# ADSP-2183xW_HPC register map
Vendor: Analog Devices; Series: ADSP-2183xW_HPC; File version: 3.0.3.517
CPU: 
Registers are 32-bit, read-write, reset 0x0 unless marked. A register's access mark holds for its fields unless they carry their own. Offsets are from the block's base; [hi:lo] are bit positions; {n}, {i} and the like mark numbered series.

## CTI1 — CSCTI_Register_Definitions
Base 0x31113000
0x00 CTICONTROL
  [0] GLBEN — Global CTI Enable
    0=DIS (Disable); 1=EN (Enable)
0x10 CTIINTACK — CTI Interrupt Acknowledge Register
  [7:0] INTACK range 0x00000000..0x000000FF — Interrupt Acknowledge
0x14 CTIAPPSET — CTI Application Trigger Set Register
  [3:0] APPSET range 0x00000000..0x0000000F — Set Channel Event
0x18 CTIAPPCLEAR — CTI Application Trigger Clear Register
  [3:0] APPCLEAR range 0x00000000..0x0000000F — Channel Clear
0x1C CTIAPPPULSE — CTI Application Pulse Register
  [3:0] Bit_0APPULSE range 0x00000000..0x0000000F — Channel Event Pulse
{0x20+4i} CTIINEN{i} (i=0..7) — CTI Trigger {i} to Channel Enable Register
  [3:0] TRIGINEN range 0x00000000..0x0000000F — Channel Trigger Input Enable
{0xA0+4i} CTIOUTEN{i} (i=0..7) — CTI Channel to Trigger {i} Enable Register
  [3:0] TRIGOUTEN range 0x00000000..0x0000000F — Channel Trigger Output Enable
0x130 CTITRIGINSTATUS — CTI Trigger In Status Register
  [7:0] TRIGINSTATUS ro — Trigger In Status
0x134 CTITRIGOUTSTATUS — CTI Trigger Out Status Register
  [7:0] TRIGOUTSTATUS ro — Trigger Output Status
0x138 CTICHINSTATUS — CTI Channel In Status Register
  [3:0] CTCHINSTATUS ro — Channel Input Status
0x13C CTICHOUTSTATUS — CTI Channel Out Status Register
  [3:0] CTCHOUTSTATUS ro — Channel Out Status
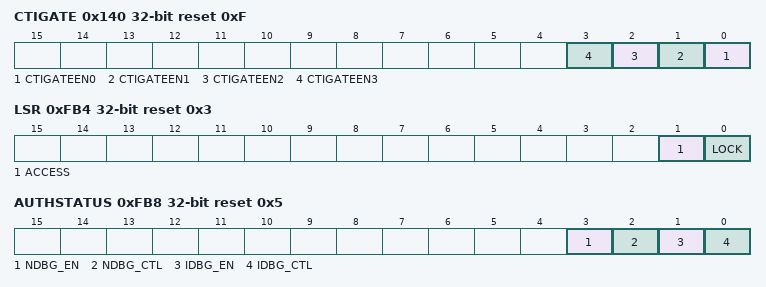
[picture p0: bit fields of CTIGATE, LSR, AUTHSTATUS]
0x140 CTIGATE reset 0xF — Enable CTI Channel Gate Register
  [n] CTIGATEEN{n} range 0x00000000..0x00000001 (n=0..3) — Enable CTICHOUT{n}
0x144 ASICCTL — External Multiplexor Control Register
  [7:0] ASICCTL range 0x00000000..0x000000FF — ASIC Control
0xEDC ITCHINACK
  [3:0] CTCHINACK range 0x00000000..0x0000000F — Set the value of the CTCHINACK outputs
0xEE0 ITTRIGINACK
  [7:0] CTTRIGINACK range 0x00000000..0x000000FF — Set the value of the CTTRIGINACK outputs
0xEE4 ITCHOUT — Integration Test Channel Output
  [3:0] CTCHOUT range 0x00000000..0x0000000F — Set CTCHOUT Output Value
0xEE8 ITTRIGOUT — Integration Test Trigger Output
  [7:0] CTTRIGOUT range 0x00000000..0x000000FF — Set the value of the CTTRIGOUT outputs
0xEEC ITCHOUTACK
  [3:0] CTCHOUTACK ro — Read the values of the CTCHOUTACK inputs
0xEF0 ITTRIGOUTACK
  [7:0] CTTRIGOUTACK ro — Read the values of the CTTRIGOUTACK inputs
0xEF4 ITCHIN — Integration Test Channel Input
  [3:0] CTCHIN ro — Read the values of the CTCHIN inputs
0xEF8 ITTRIGIN — Integration Test Trigger Input
  [7:0] CTTRIGIN ro — Read CTTRIGIN Input Values
0xF00 ITCTRL — Integration Mode Control Register
  [0] INTEGRATION_MODE range 0x00000000..0x00000001 — Integration Mode Enable
0xFA0 CLAIMSET reset 0xF — Claim Tag Set Register
  [3:0] CLAIMSET range 0x00000000..0x0000000F — Claim Tag Set Register Bits
0xFA4 CLAIMCLR — Claim Tag Clear Register
  [3:0] CLAIMCLR range 0x00000000..0x0000000F — Claim Tag Clear Register Bits
0xFB0 LAR — Lock Access Register
  [31:0] WACODE range 0x00000000..0xFFFFFFFF — Write Access Code
0xFB4 LSR reset 0x3 — Lock Status Register
  [1] ACCESS ro — Access Blocked to Device
  [0] LOCK ro — Lock Exists for Device
0xFB8 AUTHSTATUS reset 0x5 — Authentication Status
  [3] NDBG_EN ro — Non-invasive Debug Enabled Status
  [2] NDBG_CTL ro — Non-invasive Debug Controlled
  [1] IDBG_EN ro — Invasive Debug Enable Status
  [0] IDBG_CTL ro — Invasive Debug Controlled
0xFC8 DEVID reset 0x40800 — Device ID
  [19:0] DEVID ro — Device ID Field
0xFCC DEVTYPE reset 0x14 — Device Type
  [7:0] DEVTYPE ro — Device Type Field
0xFD0 PERIPHID4 reset 0x4 — Peripheral ID4
  [7:0] PID4 ro — Peripheral ID4 Field
{0xFC0+4i} PERIPHID{i} (i=5..7) — Peripheral ID{i}
  [7:0] PID{i} ro — Peripheral ID{i} Field
0xFE0 PERIPHID0 reset 0x6 — Peripheral ID0
  [7:0] PID0 ro — Peripheral ID0 Field
0xFE4 PERIPHID1 reset 0xB9 — Peripheral ID1
  [7:0] PID1 ro — Peripheral ID1 Field
0xFE8 PERIPHID2 reset 0x3B — Peripheral ID2
  [7:0] PID2 ro — Peripheral ID2 Field
0xFEC PERIPHID3 — Peripheral ID3
  [7:0] PID3 ro — Peripheral ID3 Field
0xFF0 COMPID0 reset 0xD — Component ID0
  [7:0] ID0 ro — Component ID0 Field
0xFF4 COMPID1 reset 0x90 — Component ID1
  [7:0] ID1 ro — Component ID1 Field
0xFF8 COMPID2 reset 0x5 — Component ID2
  [7:0] ID2 ro — Component ID2 Field
0xFFC COMPID3 reset 0xB1 — Component ID3
  [7:0] ID3 ro — Component ID3 Field
